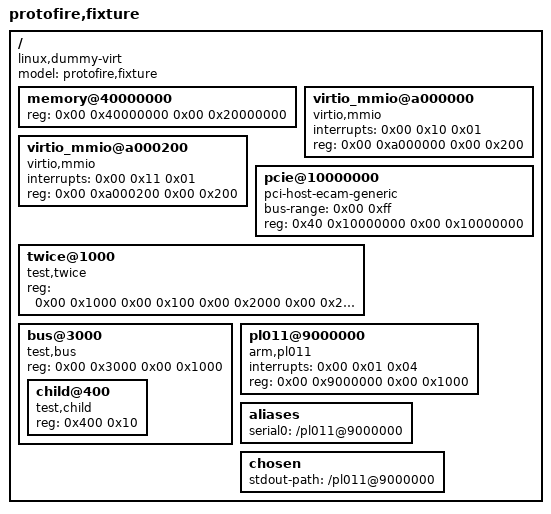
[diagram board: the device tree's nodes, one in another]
/dts-v1/;

/ {
	#address-cells = <0x02>;
	#size-cells = <0x02>;
	compatible = "linux,dummy-virt";
	model = "protofire,fixture";

	memory@40000000 {
		device_type = "memory";
		reg = <0x00 0x40000000 0x00 0x20000000>;
	};

	virtio_mmio@a000000 {
		interrupts = <0x00 0x10 0x01>;
		reg = <0x00 0xa000000 0x00 0x200>;
		compatible = "virtio,mmio";
	};

	virtio_mmio@a000200 {
		interrupts = <0x00 0x11 0x01>;
		reg = <0x00 0xa000200 0x00 0x200>;
		compatible = "virtio,mmio";
	};

	pcie@10000000 {
		#address-cells = <0x03>;
		#size-cells = <0x02>;
		device_type = "pci";
		bus-range = <0x00 0xff>;
		reg = <0x40 0x10000000 0x00 0x10000000>;
		ranges = <0x1000000 0x00 0x00 0x00 0x3eff0000 0x00 0x10000
			  0x2000000 0x00 0x10000000 0x00 0x10000000 0x00 0x2eff0000>;
		compatible = "pci-host-ecam-generic";
	};

	/* Two regions in one node, which is what the parser's cursor is for.
	   It declares no cell widths, so its reg is decoded with the root's 2+2. */
	twice@1000 {
		compatible = "test,twice";
		reg = <0x00 0x1000 0x00 0x100
		       0x00 0x2000 0x00 0x200>;
	};

	/* A node that gives its children one-cell addresses, to check that a
	   declaration applies downward and not to the declaring node. */
	bus@3000 {
		#address-cells = <0x01>;
		#size-cells = <0x01>;
		compatible = "test,bus";
		reg = <0x00 0x3000 0x00 0x1000>;

		child@400 {
			compatible = "test,child";
			reg = <0x400 0x10>;
		};
	};

	pl011@9000000 {
		clock-names = "uartclk", "apb_pclk";
		interrupts = <0x00 0x01 0x04>;
		reg = <0x00 0x9000000 0x00 0x1000>;
		compatible = "arm,pl011", "arm,primecell";
	};

	aliases {
		serial0 = "/pl011@9000000";
	};

	chosen {
		stdout-path = "/pl011@9000000";
	};
};
